# PIC32MM0064GPL036 register map
Vendor: Microchip
Architecture 32xxxx. Special function registers and configuration words.
Registers are 32-bit, read-write, reset 0x0 unless marked. A register's access mark holds for its fields unless they carry their own. Addresses are absolute, and some are shared; only a register's first bit layout is shown; lines under a group give offsets from that group; [hi:lo] are bit positions; {n}, {i} and the like mark numbered series; 'fields as' and 'values as' point back to an identical list; <NAME> marks a mode.

## Further device data
pins=1: AN4/C1INB/RP16/RB2; 2: AN11/C1INA/RB3; 3: AN12/RC0; 4: AN13/RC1; 5: RC2; 6: VSS; 7: OSC1/CLKI/AN5/RP3/OCM1C/RA2; 8: OSC2/CLKO/AN6/RP4/OCM1D/RA3; 9: SOSCI/RP5/RB4; 10: SOSCO/SCLKI/RP6/PWRLCLK/RA4; 11: RP20/RA9; 12: VSS; 13: VDD; 14: RC3; 15: PGED3/RB5; 16: PGEC3/RB6; 17: RP11/RB7; 18: TCK/RP7/U1CTS/SCK1/OCM1A/RB8; 19: NC; 20: TMS/REFCLKI/RP8/T1CK/T1G/U1RTS/U1BCLK/SDO1/C2OUT/OCM1B/INT2/RB9; 21: RC8; 22: RP19/RC9; 23: NC; 24: VCAP; 25: NC; 26: Vdd; 27: PGED2/TDO/RP17/RB10; 28: PGEC2/TDI/RP18/RB11; 29: AN7/LVDIN/RP12/RB12; 30: AN8/RP13/RB13; 31: CDAC1/AN9/RP9/RTCC/U1TX/SDI1/C1OUT/INT1/RB14; 32: AN10/REFCLKO/RP10/U1RX/SS1/INT0/RB15; 33: AVSS; 34: AVDD; 35: MCLR; 36: VREF+/AN0/RP1/OCM1E/INT3/RA0; 37: VREF-/AN1/RP2/OCM1F/RA1; 38: PGED1/AN2/C1IND/C2INB/RP14/RB0; 39: PGEC1/AN3/C1INC/C2INA/RP15/RB1; 40: NC, interrupts=0 CORE_TIMER — Core Timer; 1 CORE_SOFTWARE_0 — Core Software 0; 2 CORE_SOFTWARE_1 — Core Software 1; 3 EXTERNAL_0 — External 0; 4 EXTERNAL_1 — External 1; 5 EXTERNAL_2 — External 2; 6 EXTERNAL_3 — External 3; 7 EXTERNAL_4 — External 4; 8 CHANGE_NOTICE_A — PORT A Change Notification; 9 CHANGE_NOTICE_B — PORT B Change Notification; 10 CHANGE_NOTICE_C — PORT C Change Notification; 11 TIMER_1 — Timer 1; 12 COMPARATOR_1 — Comparator 1; 13 COMPARATOR_2 — Comparator 2; 14 RTCC — Real Time Clock Alarm; 15 ADC — ADC Conversion Done; 16 CRC — CRC; 17 HLVD — HLVD; 18 CLC1 — Logic Cell 1; 19 CLC2 — Logic Cell 2; 20 SPI1_ERR — SPI 1 Error; 21 SPI1_TX — SPI 1 Transmission; 22 SPI1_RX — SPI 1 Reception; 23 UART1_RX — UART 1 Reception; 24 UART1_TX — UART 1 Transmission; 25 UART1_ERR — UART 1 Error; 29 CCP1 — CCP 1 Input Capture or Output Compare; 30 CCT1 — CCP 1 Timer; 31 CCP2 — CCP 2 Input Capture or Output Compare; 32 CCT2 — CCP 2 Timer; 33 CCP3 — CCP 3 Input Capture or Output Compare; 34 CCT3 — CCP 3 Timer; 37 SPI2_ERR — SPI 2 Error; 38 SPI2_TX — SPI 2 Transmission; 39 SPI2_RX — SPI 2 Reception; 40 UART2_RX — UART 2 Reception; 41 UART2_TX — UART 2 Transmission; 42 UART2_ERR — UART 2 Error; 46 NVM — NVM Program or Erase Complete; 47 PERFORMANCE_COUNTER — Core Performance Counter

## RTCC
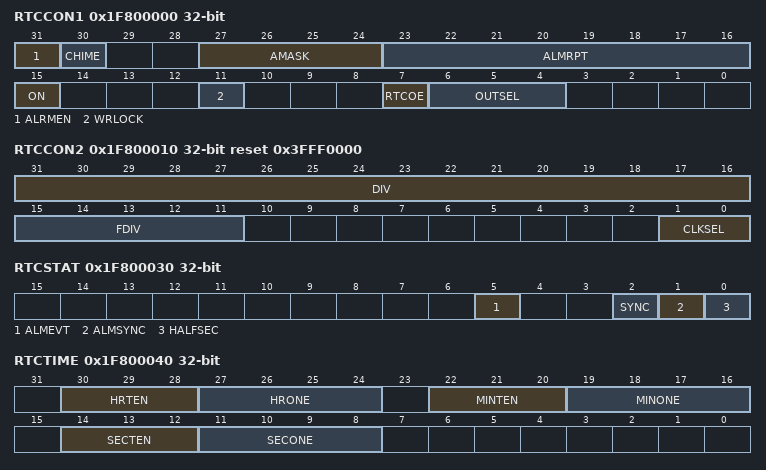
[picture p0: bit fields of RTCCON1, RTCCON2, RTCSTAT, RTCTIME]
0x1F800000 RTCCON1
  [31] ALRMEN, [30] CHIME, [27:24] AMASK, [23:16] ALMRPT, [15] ON, [11] WRLOCK, [7] RTCOE, [6:4] OUTSEL
0x1F800010 RTCCON2 reset 0x3FFF0000
  [31:16] DIV, [15:11] FDIV, [1:0] CLKSEL
0x1F800030 RTCSTAT
  [5] ALMEVT — (can only be cleared)
  [2] SYNC ro
  [1] ALMSYNC ro
  [0] HALFSEC ro
0x1F800040 RTCTIME
  [30:28] HRTEN, [27:24] HRONE, [22:20] MINTEN, [19:16] MINONE, [14:12] SECTEN, [11:8] SECONE
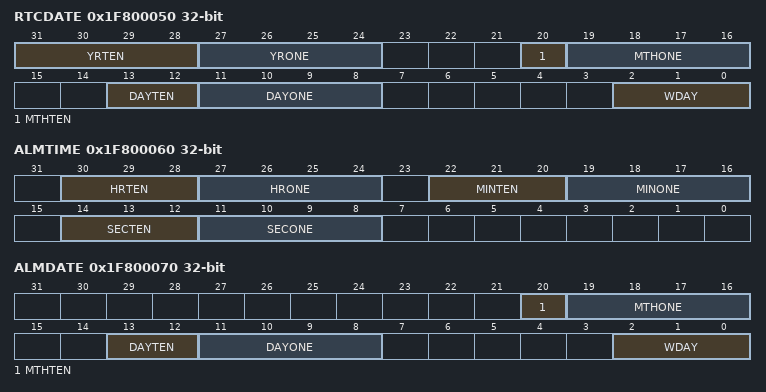
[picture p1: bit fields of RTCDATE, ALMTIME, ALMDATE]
0x1F800050 RTCDATE
  [31:28] YRTEN, [27:24] YRONE, [20] MTHTEN, [19:16] MTHONE, [13:12] DAYTEN, [11:8] DAYONE, [2:0] WDAY
0x1F800060 ALMTIME
  fields as RTCTIME
0x1F800070 ALMDATE
  [20] MTHTEN, [19:16] MTHONE, [13:12] DAYTEN, [11:8] DAYONE, [2:0] WDAY

## CCP1
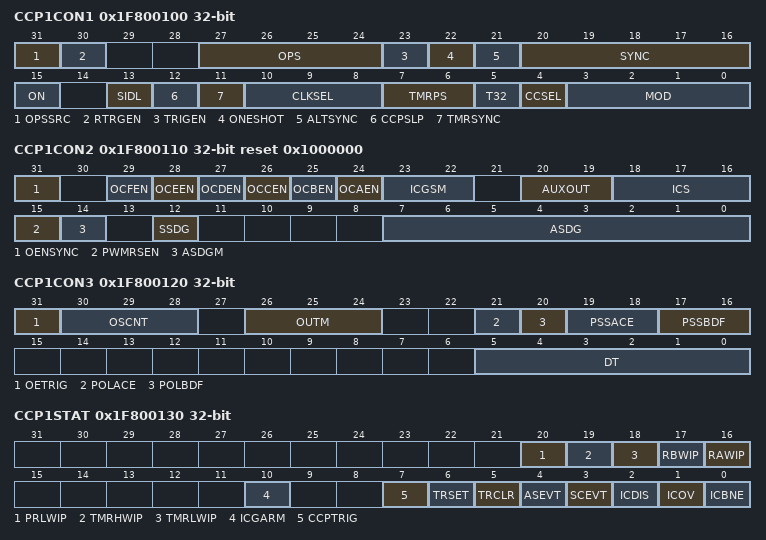
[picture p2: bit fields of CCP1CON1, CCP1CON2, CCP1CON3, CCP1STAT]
0x1F800100 CCP1CON1
  [31] OPSSRC, [30] RTRGEN, [27:24] OPS, [23] TRIGEN, [22] ONESHOT, [21] ALTSYNC, [20:16] SYNC, [15] ON, [13] SIDL, [12] CCPSLP, [11] TMRSYNC, [10:8] CLKSEL, [7:6] TMRPS, [5] T32, [4] CCSEL, [3:0] MOD
0x1F800110 CCP1CON2 reset 0x1000000
  [31] OENSYNC, [29] OCFEN, [28] OCEEN, [27] OCDEN, [26] OCCEN, [25] OCBEN, [24] OCAEN, [23:22] ICGSM, [20:19] AUXOUT, [18:16] ICS, [15] PWMRSEN, [14] ASDGM, [12] SSDG, [7:0] ASDG
0x1F800120 CCP1CON3
  [31] OETRIG, [30:28] OSCNT, [26:24] OUTM, [21] POLACE, [20] POLBDF, [19:18] PSSACE, [17:16] PSSBDF, [5:0] DT
0x1F800130 CCP1STAT
  [20] PRLWIP
  [19] TMRHWIP
  [18] TMRLWIP
  [17] RBWIP
  [16] RAWIP
  [10] ICGARM
  [7] CCPTRIG ro
  [6] TRSET
  [5] TRCLR
  [4] ASEVT — (can only be cleared)
  [3] SCEVT — (can only be cleared)
  [2] ICDIS ro
  [1] ICOV — (can only be cleared)
  [0] ICBNE ro
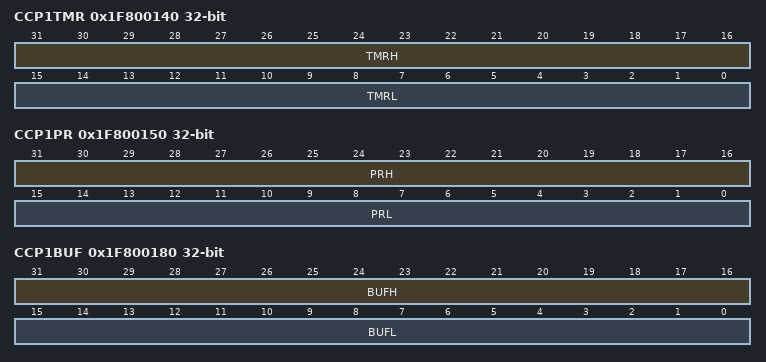
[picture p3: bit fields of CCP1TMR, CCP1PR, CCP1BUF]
0x1F800140 CCP1TMR
  [31:16] TMRH, [15:0] TMRL
0x1F800150 CCP1PR
  [31:16] PRH, [15:0] PRL
0x1F800160 CCP1RA
  [15:0] CMPA
0x1F800170 CCP1RB
  [15:0] CMPB
0x1F800180 CCP1BUF
  [31:16] BUFH, [15:0] BUFL
